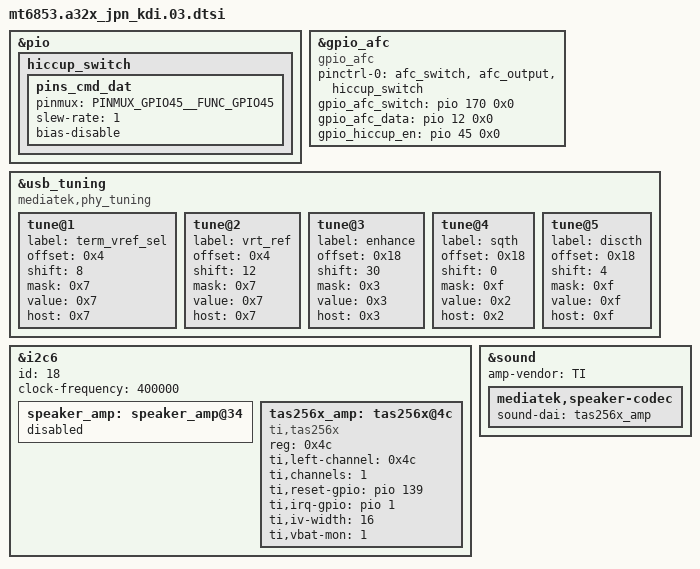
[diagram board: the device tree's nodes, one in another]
/*
 * Generated by Samsung
 * If these files should be changed, then please make a sync with MTK
*/

#include "../../mediatek/k6853v1_64_titan/gpio03_jpn.dtsi"
#include "mt6853-a32x_common.dtsi"
#include "mt6853-a32x_camera_03.dtsi"
#include "mt6853-a32x_jpn_gripsensor_00.dtsi"
#include "display_lcd_a32x_common.dtsi"
#include "mt6853_input_a32x_05.dtsi"

&pio {
	hiccup_switch: hiccup_switch {
		pins_cmd_dat {
			pinmux = <PINMUX_GPIO45__FUNC_GPIO45>;
			slew-rate = <1>;
			bias-disable;
		};
	};
};

&gpio_afc {
	compatible = "gpio_afc";
	pinctrl-names = "default";
	pinctrl-0 = <&afc_switch &afc_output &hiccup_switch>;
	status = "okay";
	gpio_afc_switch = <&pio 170 0x0>;
	gpio_afc_data = <&pio 12 0x0>;
	gpio_hiccup_en = <&pio 45 0x0>;
};

&usb_tuning {
	compatible = "mediatek,phy_tuning";

	tune@1 {
		label = "term_vref_sel";
		offset = <0x4>;
		shift = <8>;
		mask = <0x7>;
		value = <0x7>;
		host = <0x7>;
	};

	tune@2 {
		label = "vrt_ref";
		offset = <0x4>;
		shift = <12>;
		mask = <0x7>;
		value = <0x7>;
		host = <0x7>;
	};

	tune@3 {
		label = "enhance";
		offset = <0x18>;
		shift = <30>;
		mask = <0x3>;
		value = <0x3>;
		host = <0x3>;
	};

	tune@4 {
		label = "sqth";
		offset = <0x18>;
		shift = <0>;
		mask = <0xf>;
		value = <0x2>;
		host = <0x2>;
	};

	tune@5 {
		label = "discth";
		offset = <0x18>;
		shift = <4>;
		mask = <0xf>;
		value = <0xf>;
		host = <0xf>;
	};
};

&i2c6 {
	speaker_amp: speaker_amp@34 {
		status = "disabled";
	};
};

&i2c6 {
	status = "okay";
	id = <18>;
	clock-frequency = <400000>;
	#address-cells = <1>;
	#size-cells = <0>;

	tas256x_amp: tas256x@4c {
		#sound-dai-cells = <0>;
		compatible = "ti,tas256x";
		reg = <0x4c>;
		ti,left-channel = <0x4c>;
		ti,channels = <1>;
		ti,reset-gpio = <&pio 139 0>;
		ti,irq-gpio = <&pio 1 0>;
		status = "okay";
		ti,iv-width = <16>;
		ti,vbat-mon = <1>;
	};
};

&sound {
	amp-vendor = "TI";
	mediatek,speaker-codec {
		sound-dai = <&tas256x_amp>;
	};
};
/*End of this file, DO NOT ADD ANYTHING HERE*/
